# BlockB: IP-XACT component
VLNV example.org:FutureLib:BlockB:1.0

## Address spaces and blocks
BlockBMap.BlockBRegs: base 0x0000, range 0x100, width 32

## Registers
Registers are 32-bit, read-write, no defined reset value unless marked. A register's access mark holds for its fields unless they carry their own. Offsets are from the block's base; lines under a group give offsets from that group; [hi:lo] are bit positions; {n}, {i} and the like mark numbered series; 'fields as' and 'values as' point back to an identical list; <NAME> marks a mode.

## BlockBMap.BlockBRegs
Base 0x00000000
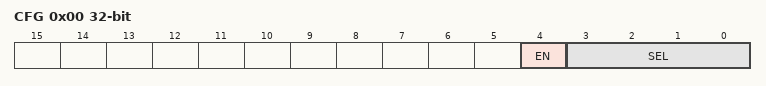
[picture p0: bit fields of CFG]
0x00 CFG
  [4] EN, [3:0] SEL
0x04 COUNT ro
  [15:0] VAL
0x08 THRESH
  [7:0] THRESHOLD
0x0C EVENT wo
  [7:0] EVENT_ID
0x10 MASK
  [7:0] MASKVAL
